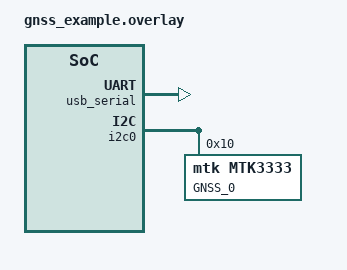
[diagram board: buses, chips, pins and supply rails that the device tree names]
/ {
    aliases {
        gnss = &gnssnode;
    };
	chosen {
		zephyr,console = &usb_serial;
		zephyr,shell-uart = &usb_serial;
	};
};

&usb_serial {
	status = "okay";
};

&i2c0 {
    status = "okay";

    gnssnode: gnss@10 {
        compatible = "mtk,mtk3333";
        reg = <0x10>;
        label = "GNSS_0";
        status = "okay";
    };
};
